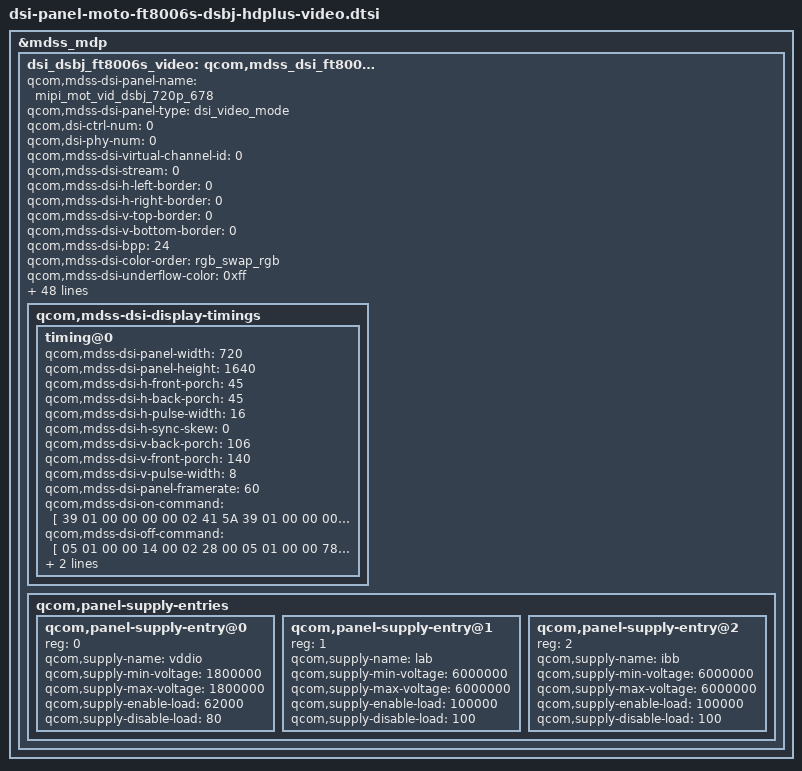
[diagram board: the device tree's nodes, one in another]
/* Copyright (c) 2015, 2018, The Linux Foundation. All rights reserved.
 *
 * This program is free software; you can redistribute it and/or modify
 * it under the terms of the GNU General Public License version 2 and
 * only version 2 as published by the Free Software Foundation.
 *
 * This program is distributed in the hope that it will be useful,
 * but WITHOUT ANY WARRANTY; without even the implied warranty of
 * MERCHANTABILITY or FITNESS FOR A PARTICULAR PURPOSE.  See the
 * GNU General Public License for more details.
 */

/*---------------------------------------------------------------------------
 * This file is autogenerated file using gcdb parser. Please do not edit it.
 * Update input XML file to add a new entry or update variable in this file
 * VERSION = "1.0"
 *---------------------------------------------------------------------------
 */

&mdss_mdp {
	dsi_dsbj_ft8006s_video:qcom,mdss_dsi_ft8006s_dsbj_video {
		qcom,mdss-dsi-panel-name ="mipi_mot_vid_dsbj_720p_678";
		qcom,mdss-dsi-panel-type = "dsi_video_mode";

		qcom,dsi-ctrl-num = <0>;
		qcom,dsi-phy-num = <0>;

		qcom,mdss-dsi-virtual-channel-id = <0>;
		qcom,mdss-dsi-stream = <0>;
		qcom,mdss-dsi-h-left-border = <0>;
		qcom,mdss-dsi-h-right-border = <0>;
		qcom,mdss-dsi-v-top-border = <0>;
		qcom,mdss-dsi-v-bottom-border = <0>;
		qcom,mdss-dsi-bpp = <24>;
		qcom,mdss-dsi-color-order = "rgb_swap_rgb";
		qcom,mdss-dsi-underflow-color = <0xff>;
		qcom,mdss-dsi-border-color = <0>;
		qcom,mdss-dsi-h-sync-pulse = <0>;
		qcom,mdss-dsi-traffic-mode = "non_burst_sync_event";
		qcom,mdss-dsi-lane-map = "lane_map_0123";
		qcom,mdss-dsi-bllp-eof-power-mode;
		qcom,mdss-dsi-bllp-power-mode;
		qcom,mdss-dsi-tx-eot-append;
		qcom,mdss-dsi-lane-0-state;
		qcom,mdss-dsi-lane-1-state;
		qcom,mdss-dsi-lane-2-state;
		qcom,mdss-dsi-lane-3-state;
		qcom,mdss-dsi-dma-trigger = "trigger_sw";
		qcom,mdss-dsi-mdp-trigger = "none";
		qcom,mdss-dsi-lp11-init;
		qcom,mdss-dsi-reset-always-high;
		qcom,mdss-panel-on-tp-rst-enable;
		qcom,mdss-panel-on-rst-pull-down;
		qcom,mdss-dsi-tp-rst-gpio = <&tlmm 66 0>;
		qcom,mdss-dsi-tp-rst-post-ms = <3>;
		qcom,mdss-dsi-reset-sequence = <1 35>, <1 5>;
		qcom,mdss-pan-physical-width-dimension = <69>;
		qcom,mdss-pan-physical-height-dimension = <158>;

		qcom,mdss-dsi-bl-pmic-control-type = "bl_ctrl_dcs";
		qcom,mdss-dsi-bl-min-level = <1>;
		qcom,mdss-dsi-bl-max-level = <2047>;
		qcom,mdss-dsi-bl-default-level = <127>;

		qcom,mdss-dsi-cabc-ui-command = [15 01 00 00 00 00 02 55 00];
		qcom,mdss-dsi-cabc-ui-command-state = "dsi_hs_mode";
		qcom,mdss-dsi-cabc-mv-command = [15 01 00 00 00 00 02 55 00];
		qcom,mdss-dsi-cabc-mv-command-state = "dsi_hs_mode";
		qcom,mdss-dsi-cabc-dis-command = [15 01 00 00 00 00 02 55 00];
		qcom,mdss-dsi-cabc-dis-command-state = "dsi_hs_mode";
		qcom,mdss-dsi-hbm-on-command = [39 01 00 00 00 00 03 51 FF 07];
		qcom,mdss-dsi-hbm-on-command-state = "dsi_hs_mode";
		qcom,mdss-dsi-hbm-off-command = [39 01 00 00 00 00 03 51 66 06];
		qcom,mdss-dsi-hbm-off-command-state = "dsi_hs_mode";

		qcom,mdss-dsi-display-timings {
			timing@0{
				qcom,mdss-dsi-panel-width = <720>;
				qcom,mdss-dsi-panel-height = <1640>;
				qcom,mdss-dsi-h-front-porch = <45>;
				qcom,mdss-dsi-h-back-porch = <45>;
				qcom,mdss-dsi-h-pulse-width = <16>;
				qcom,mdss-dsi-h-sync-skew = <0>;
				qcom,mdss-dsi-v-back-porch = <106>;
				qcom,mdss-dsi-v-front-porch = <140>;
				qcom,mdss-dsi-v-pulse-width = <8>;
				qcom,mdss-dsi-panel-framerate = <60>;
				qcom,mdss-dsi-on-command = [
					39 01 00 00 00 00 02 41 5A
					39 01 00 00 00 00 03 41 5A 24
					39 01 00 00 00 00 02 90 5A
					39 01 00 00 00 00 03 41 5A 03
					39 01 00 00 00 00 03 80 25 01
					39 01 00 00 00 00 03 41 5A 08
					39 01 00 00 00 00 04 80 C8 2C 01
					39 01 00 00 00 00 03 41 5A 09
					39 01 00 00 00 00 11 80 5A 51 B5 2A 6C E5 4A 01 40 62 0F 82 20 08 F0 B7
					39 01 00 00 00 00 11 90 00 24 42 0A E3 91 A4 F0 B9 4D 69 20 41 81 26 00
					39 01 00 00 00 00 11 A0 51 55 55 00 A0 4C 06 11 0D 60 5A FF FF 03 A5 E6
					39 01 00 00 00 00 11 B0 08 C9 16 64 0B 00 00 11 07 60 00 FF FF 03 FF 34
					39 01 00 00 00 00 09 C0 0C 3F 1F 9F 0F 00 08 00
					39 01 00 00 00 00 03 41 5A 0A
					39 01 00 00 00 00 11 80 E0 83 8D 03 00 0B 16 21 30 40 45 78 45 85 AC 70
					39 01 00 00 00 00 11 90 90 5F 5A 49 38 27 1B 0B 00 0B 16 21 30 40 45 78
					39 01 00 00 00 00 0D A0 45 85 AC 70 90 5F 5A 49 38 27 1B 0B
					39 01 00 00 00 00 03 41 5A 0B
					39 01 00 00 00 00 11 80 00 00 20 44 08 00 60 47 00 00 10 22 04 00 B0 23
					39 01 00 00 00 00 03 90 15 00
					39 01 00 00 00 00 03 41 5A 0C
					39 01 00 00 00 00 11 80 FA 68 68 41 B3 75 B0 04 00 60 15 00 50 15 56 51
					39 01 00 00 00 00 11 90 15 55 61 15 00 60 15 00 50 15 56 51 15 55 61 95
					39 01 00 00 00 00 11 A0 AB 18 00 05 00 05 00 05 80 4C 29 84 52 01 09 00
					39 01 00 00 00 00 03 B0 00 00
					39 01 00 00 00 00 03 41 5A 0D
					39 01 00 00 00 00 08 80 F0 B1 71 EF 4B C0 80
					39 01 00 00 00 00 03 41 5A 0E
					39 01 00 00 00 00 09 80 FF 01 55 55 23 88 88 1C
					39 01 00 00 00 00 03 41 5A 0F
					39 01 00 00 00 00 11 80 D1 07 70 40 13 38 C4 08 52 51 58 49 03 52 4C 4C
					39 01 00 00 00 00 11 90 68 68 68 4C 4C FC 10 00 20 06 C2 00 04 06 0C 00
					39 01 00 00 00 00 05 A0 00 92 00 00
					39 01 00 00 00 00 03 41 5A 10
					39 01 00 00 00 00 11 80 00 00 03 E7 1F 17 20 48 90 12 D1 18 30 88 41 8A
					39 01 00 00 00 00 10 90 39 28 A9 C5 9A 7B F0 07 7E E0 07 7E 20 10 00
					39 01 00 00 00 00 03 41 5A 11
					39 01 00 00 00 00 11 80 49 77 03 40 CA F3 FF 83 30 08 C4 06 A1 D8 24 18
					39 01 00 00 00 00 11 90 30 C6 66 C1 80 31 15 CB E5 D2 68 6C 36 1D 04 C8
					39 01 00 00 00 00 11 A0 B0 D9 88 60 B0 81 40 1A 1B 48 63 03 B9 00 1C 80
					39 01 00 00 00 00 11 B0 50 30 00 E0 E1 01 00 28 0E 06 43 55 55 55 55 55
					39 01 00 00 00 00 11 C0 95 88 88 88 88 88 C8 08 86 C6 E3 81 00 20 00 21
					39 01 00 00 00 00 11 D0 42 88 00 00 00 00 40 00 00 31 04 41 06 00 00 00
					39 01 00 00 00 00 11 E0 00 92 04 00 92 04 00 00 00 00 92 04 00 85 11 0C
					39 01 00 00 00 00 10 F0 00 00 40 00 00 00 00 5E 4A 01 78 00 08 00 00
					39 01 00 00 00 00 03 41 5A 12
					39 01 00 00 00 00 11 80 00 00 00 00 00 02 03 00 00 00 00 02 03 01 41 37
					39 01 00 00 00 00 11 90 F1 E7 00 00 00 00 00 00 00 00 00 00 00 2D 23 05
					39 01 00 00 00 00 08 A0 FB 08 2D 23 05 FB 0C
					39 01 00 00 00 00 03 41 5A 13
					39 01 00 00 00 00 11 80 FD 0F 00 0C 00 00 00 00 01 08 01 1C 44 0C CE E7
					39 01 00 00 00 00 0F 90 62 0E 24 98 AC 21 01 00 D0 93 24 49 06 20
					39 01 00 00 00 00 03 41 5A 14
					39 01 00 00 00 00 11 80 01 02 41 36 E9 EF F7 FB FD 7E 01 00 00 9A C5 88
					39 01 00 00 00 00 11 90 E8 3D 20 36 44 EF 01 31 23 7A 8F 81 09 D1 7B 00
					39 01 00 00 00 00 11 A0 AC 88 DE 63 4C 00 DF 0F 80 37 03 00 00 00 00 20
					39 01 00 00 00 00 11 B0 C3 41 99 6C 00 00 00 00 00 5C B3 35 2B 00 40 A1
					39 01 00 00 00 00 11 C0 50 78 07 E4 F4 80 51 1C 6F 80 9C 1E 30 8A E3 05
					39 01 00 00 00 00 11 D0 90 D3 03 46 71 BC 02 72 7A C0 28 8E 77 41 4E 0F
					39 01 00 00 00 00 11 E0 18 C5 F1 26 C8 E9 01 A3 38 DE 03 39 3D 60 14 C7
					39 01 00 00 00 00 11 F0 5B 20 A7 07 8C E2 18 01 BF DF 08 00 00 00 00 00
					39 01 00 00 00 00 03 41 5A 15
					39 01 00 00 00 00 11 80 00 00 00 00 00 00 00 00 00 00 00 00 06 C0 FF F7
					39 01 00 00 00 00 11 90 93 01 3A 5B C7 A8 95 05 91 91 D3 31 6A 65 41 64
					39 01 00 00 00 00 11 A0 64 00 00 00 00 00 00 00 00 00 00 00 00 00 00 90
					39 01 00 00 00 00 11 B0 59 A1 28 14 00 00 00 00 13 00 F0 00 94 D6 34 D3
					39 01 00 00 00 00 11 C0 14 04 29 41 30 0C 45 71 1C D3 0C C3 68 6A D3 D4
					39 01 00 00 00 00 11 D0 34 41 90 62 18 04 21 08 00 30 CD 30 94 A0 D6 34
					39 01 00 00 00 00 11 E0 D3 14 04 29 00 20 08 04 61 18 D3 0C 43 48 6A D3
					39 01 00 00 00 00 11 F0 D4 34 41 90 72 1C 45 31 0C 41 30 CD 30 9C 22 C0
					39 01 00 00 00 00 03 41 5A 16
					39 01 00 00 00 00 11 80 C3 43 41 01 00 00 00 00 00 00 00 00 00 00 00 00
					39 01 00 00 00 00 07 90 00 00 00 00 F0 20
					39 01 00 00 00 00 03 41 5A 18
					39 01 00 00 00 00 11 80 EF BD F7 DE 7B EF BD 07 08 08 0A 0C 0C 0C 0C 0C
					39 01 00 00 00 00 11 90 0C 0C 0C 5C 09 A8 AA AA AA AA AA AA AA AA AA 5A
					39 01 00 00 00 00 11 A0 59 59 59 59 59 59 59 59 59 59 59 09 04 FF 00 80
					39 01 00 00 00 00 10 B0 80 00 04 20 00 01 08 40 00 02 10 80 00 04 00
					39 01 00 00 00 00 03 41 5A 19
					39 01 00 00 00 00 11 80 C0 AF A3 9B 92 8D 8A 86 84 83 82 81 00 50 F6 CF
					39 01 00 00 00 00 11 90 FC 2F F3 EF CF BF 0F FF AF B5 71 0E 6C 4A 69 08
					39 01 00 00 00 00 05 A0 00 00 08 00
					39 01 00 00 00 00 03 41 5A 1A
					39 01 00 00 00 00 11 80 00 04 08 0C 00 10 14 18 1C 00 20 28 30 38 00 40
					39 01 00 00 00 00 11 90 48 50 58 00 60 68 70 78 00 80 88 90 98 00 A0 A8
					39 01 00 00 00 00 11 A0 B0 B8 00 C0 C8 D0 D8 00 E0 E8 F0 F8 00 FC FE FF
					39 01 00 00 00 00 11 B0 00 00 04 08 0C 00 10 14 18 1C 00 20 28 30 38 00
					39 01 00 00 00 00 11 C0 40 48 50 58 00 60 68 70 78 00 80 88 90 98 00 A0
					39 01 00 00 00 00 11 D0 A8 B0 B8 00 C0 C8 D0 D8 00 E0 E8 F0 F8 00 FC FE
					39 01 00 00 00 00 11 E0 FF 00 00 04 08 0C 00 10 14 18 1C 00 20 28 30 38
					39 01 00 00 00 00 11 F0 00 40 48 50 58 00 60 68 70 78 00 80 88 90 98 00
					39 01 00 00 00 00 03 41 5A 1B
					39 01 00 00 00 00 11 80 A0 A8 B0 B8 00 C0 C8 D0 D8 00 E0 E8 F0 F8 00 FC
					39 01 00 00 00 00 05 90 FE FF 00 00
					39 01 00 00 00 00 03 41 5A 20
					39 01 00 00 00 00 08 80 87 00 00 00 00 00 00
					39 01 00 00 00 00 03 41 5A 22
					39 01 00 00 00 00 0E 80 2D D3 00 55 55 55 55 55 55 55 55 9F 00
					39 01 00 00 00 00 03 41 5A 23
					39 01 00 00 00 00 11 80 01 05 00 05 00 00 00 00 00 00 00 00 00 00 00 00
					39 01 00 00 00 00 0D 90 FF 0F 00 00 00 03 00 00 00 FF 07 35
					39 01 00 00 00 00 03 41 5A 24
					39 01 00 00 00 00 11 80 00 03 00 FF FF 20 00 00 00 00 00 00 00 00 ED 8B
					39 01 00 00 00 00 11 90 5A 5A 5A 55 00 00 00 00 00 00 00 00 00 00 00 00
					39 01 00 00 00 00 02 42 24
					39 01 00 00 00 00 02 90 00
					39 01 00 00 00 00 03 41 5A 2F
					39 01 00 00 00 00 02 19 01
					39 01 00 00 00 00 02 4C 03
					05 01 00 00 78 00 01 11
					05 01 00 00 00 00 01 29
					39 01 00 00 00 00 03 51 66 06
					39 01 00 00 00 00 02 53 24
					39 01 00 00 0A 00 02 55 00];
				qcom,mdss-dsi-off-command = [
					05 01 00 00 14 00 02 28 00
					05 01 00 00 78 00 02 10 00
					39 01 00 00 00 00 02 17 5A
					39 01 00 00 96 00 02 18 5A
					];
				qcom,mdss-dsi-on-command-state = "dsi_lp_mode";
				qcom,mdss-dsi-off-command-state = "dsi_lp_mode";
			};
		};

		qcom,panel-supply-entries {
			#address-cells = <1>;
			#size-cells = <0>;

			qcom,panel-supply-entry@0 {
				reg = <0>;
				qcom,supply-name = "vddio";
				qcom,supply-min-voltage = <1800000>;
				qcom,supply-max-voltage = <1800000>;
				qcom,supply-enable-load = <62000>;
				qcom,supply-disable-load = <80>;
			};

			qcom,panel-supply-entry@1 {
				reg = <1>;
				qcom,supply-name = "lab";
				qcom,supply-min-voltage = <6000000>;
				qcom,supply-max-voltage = <6000000>;
				qcom,supply-enable-load = <100000>;
				qcom,supply-disable-load = <100>;
			};

			qcom,panel-supply-entry@2 {
				reg = <2>;
				qcom,supply-name = "ibb";
				qcom,supply-min-voltage = <6000000>;
				qcom,supply-max-voltage = <6000000>;
				qcom,supply-enable-load = <100000>;
				qcom,supply-disable-load = <100>;
			};
		};
	};
};

